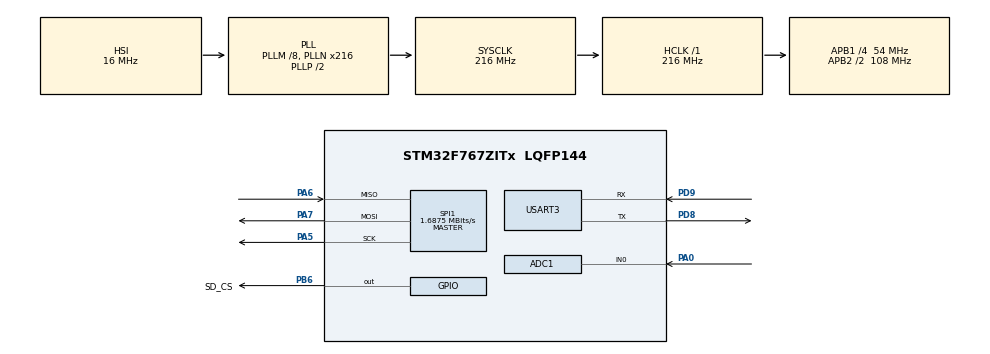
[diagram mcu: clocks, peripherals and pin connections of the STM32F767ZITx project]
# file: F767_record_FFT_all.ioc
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ADC1.Channel-0\#ChannelRegularConversion=ADC_CHANNEL_0
ADC1.DMAContinuousRequests=ENABLE
ADC1.ExternalTrigConv=ADC_EXTERNALTRIGCONV_T2_TRGO
ADC1.NbrOfConversionFlag=1
ADC1.Rank-0\#ChannelRegularConversion=1
ADC1.SamplingTime-0\#ChannelRegularConversion=ADC_SAMPLETIME_28CYCLES
ADC1.master=1
CORTEX_M7.default_mode_Activation=1
Dma.ADC1.0.Direction=DMA_PERIPH_TO_MEMORY
Dma.ADC1.0.FIFOMode=DMA_FIFOMODE_DISABLE
Dma.ADC1.0.Instance=DMA2_Stream0
Dma.ADC1.0.MemDataAlignment=DMA_MDATAALIGN_HALFWORD
Dma.ADC1.0.MemInc=DMA_MINC_ENABLE
Dma.ADC1.0.Mode=DMA_CIRCULAR
Dma.ADC1.0.PeriphDataAlignment=DMA_PDATAALIGN_HALFWORD
Dma.ADC1.0.PeriphInc=DMA_PINC_DISABLE
Dma.ADC1.0.Priority=DMA_PRIORITY_HIGH
Dma.Request0=ADC1
FATFS._CODE_PAGE=437
Mcu.Family=STM32F7
Mcu.Name=STM32F767ZITx
Mcu.Package=LQFP144
NVIC.DMA2_Stream0_IRQn=true\:0\:0\:false\:false\:true\:false\:true\:true
NVIC.PriorityGroup=NVIC_PRIORITYGROUP_4
NVIC.USART3_IRQn=true\:0\:0\:false\:false\:true\:true\:true\:true
PA0/WKUP.Signal=ADCx_IN0
PA5.Mode=Full_Duplex_Master
PA5.Signal=SPI1_SCK
PA6.Mode=Full_Duplex_Master
PA6.Signal=SPI1_MISO
PA7.Mode=Full_Duplex_Master
PA7.Signal=SPI1_MOSI
PB6.GPIO_Label=SD_CS
PB6.GPIO_Speed=GPIO_SPEED_FREQ_HIGH
PB6.PinState=GPIO_PIN_SET
PB6.Signal=GPIO_Output
PD8.Mode=Asynchronous
PD8.Signal=USART3_TX
PD9.Mode=Asynchronous
PD9.Signal=USART3_RX
ProjectManager.HeapSize=0x200
ProjectManager.StackSize=0x400
ProjectManager.TargetToolchain=STM32CubeIDE
RCC.AHBFreq_Value=216000000
RCC.APB1CLKDivider=RCC_HCLK_DIV4
RCC.APB1Freq_Value=54000000
RCC.APB1TimFreq_Value=108000000
RCC.APB2CLKDivider=RCC_HCLK_DIV2
RCC.APB2Freq_Value=108000000
RCC.APB2TimFreq_Value=216000000
RCC.CortexFreq_Value=216000000
RCC.HCLKFreq_Value=216000000
RCC.HSE_VALUE=25000000
RCC.HSI_VALUE=16000000
RCC.LSE_VALUE=32768
RCC.PLLM=8
RCC.PLLN=216
RCC.SYSCLKFreq_VALUE=216000000
RCC.SYSCLKSource=RCC_SYSCLKSOURCE_PLLCLK
RCC.USBFreq_Value=216000000
RCC.VCOOutputFreq_Value=432000000
SH.ADCx_IN0.0=ADC1_IN0,IN0
SPI1.BaudRatePrescaler=SPI_BAUDRATEPRESCALER_64
SPI1.CalculateBaudRate=1.6875 MBits/s
SPI1.DataSize=SPI_DATASIZE_8BIT
SPI1.Direction=SPI_DIRECTION_2LINES
SPI1.Mode=SPI_MODE_MASTER
SPI1.NSSPMode=SPI_NSS_PULSE_DISABLE
SPI1.VirtualType=VM_MASTER
TIM2.Period=3374
TIM2.TIM_MasterOutputTrigger=TIM_TRGO_UPDATE
TIM2.TIM_MasterSlaveMode=TIM_MASTERSLAVEMODE_DISABLE
USART3.VirtualMode-Asynchronous=VM_ASYNC
VP_FATFS_VS_Generic.Mode=User_defined
VP_TIM2_VS_ClockSourceINT.Mode=Internal
board=custom

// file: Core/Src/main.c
/* USER CODE BEGIN Header */
/* F767_record_FFT_all */
/**
  ******************************************************************************
  * @file           : main.c
  * @brief          : Main program body
  ******************************************************************************
  * @attention
  *
  * Copyright (c) 2026 STMicroelectronics.
  * All rights reserved.
  *
  * This software is licensed under terms that can be found in the LICENSE file
  * in the root directory of this software component.
  * If no LICENSE file comes with this software, it is provided AS-IS.
  *
  ******************************************************************************
  */
/* USER CODE END Header */
#include "main.h"
#include "adc.h"
#include "dma.h"
#include "fatfs.h"
#include "spi.h"
#include "tim.h"
#include "usart.h"
#include "gpio.h"

/* USER CODE BEGIN Includes */
#include "app_main.h"
/* USER CODE END Includes */

void SystemClock_Config(void);
static void MPU_Config(void);

int main(void)
{

  /* MPU Configuration--------------------------------------------------------*/
  MPU_Config();

  /* MCU Configuration--------------------------------------------------------*/

  /* Reset of all peripherals, Initializes the Flash interface and the Systick. */
  HAL_Init();

  /* Configure the system clock */
  SystemClock_Config();

  /* Initialize all configured peripherals */
  MX_GPIO_Init();
  MX_DMA_Init();
  MX_ADC1_Init();
  MX_TIM2_Init();
  MX_SPI1_Init();
  MX_USART3_UART_Init();
  MX_FATFS_Init();
  /* USER CODE BEGIN 2 */
  // HAL_UART_Transmit(&huart3, (uint8_t*)"MAIN START\r\n", 12, 1000);
  APP_Init();
  /* USER CODE END 2 */

  /* Infinite loop */
  /* USER CODE BEGIN WHILE */
  while (1)
  {
    // HAL_UART_Transmit(&huart3, (uint8_t*)"HELLO\r\n", 7, 1000);
    APP_Loop();
    /* USER CODE END WHILE */

  }
}

void SystemClock_Config(void)
{
  RCC_OscInitTypeDef RCC_OscInitStruct = {0};
  RCC_ClkInitTypeDef RCC_ClkInitStruct = {0};

  /** Configure the main internal regulator output voltage
  */
  __HAL_RCC_PWR_CLK_ENABLE();
  __HAL_PWR_VOLTAGESCALING_CONFIG(PWR_REGULATOR_VOLTAGE_SCALE1);

  /** Initializes the RCC Oscillators according to the specified parameters
  * in the RCC_OscInitTypeDef structure.
  */
  RCC_OscInitStruct.OscillatorType = RCC_OSCILLATORTYPE_HSI;
  RCC_OscInitStruct.HSIState = RCC_HSI_ON;
  RCC_OscInitStruct.HSICalibrationValue = RCC_HSICALIBRATION_DEFAULT;
  RCC_OscInitStruct.PLL.PLLState = RCC_PLL_ON;
  RCC_OscInitStruct.PLL.PLLSource = RCC_PLLSOURCE_HSI;
  RCC_OscInitStruct.PLL.PLLM = 8;
  RCC_OscInitStruct.PLL.PLLN = 216;
  RCC_OscInitStruct.PLL.PLLP = RCC_PLLP_DIV2;
  RCC_OscInitStruct.PLL.PLLQ = 2;
  RCC_OscInitStruct.PLL.PLLR = 2;
  if (HAL_RCC_OscConfig(&RCC_OscInitStruct) != HAL_OK)
  {
    Error_Handler();
  }

  /** Activate the Over-Drive mode
  */
  if (HAL_PWREx_EnableOverDrive() != HAL_OK)
  {
    Error_Handler();
  }

  /** Initializes the CPU, AHB and APB buses clocks
  */
  RCC_ClkInitStruct.ClockType = RCC_CLOCKTYPE_HCLK|RCC_CLOCKTYPE_SYSCLK
                              |RCC_CLOCKTYPE_PCLK1|RCC_CLOCKTYPE_PCLK2;
  RCC_ClkInitStruct.SYSCLKSource = RCC_SYSCLKSOURCE_PLLCLK;
  RCC_ClkInitStruct.AHBCLKDivider = RCC_SYSCLK_DIV1;
  RCC_ClkInitStruct.APB1CLKDivider = RCC_HCLK_DIV4;
  RCC_ClkInitStruct.APB2CLKDivider = RCC_HCLK_DIV2;

  if (HAL_RCC_ClockConfig(&RCC_ClkInitStruct, FLASH_LATENCY_7) != HAL_OK)
  {
    Error_Handler();
  }
}

/* USER CODE BEGIN 4 */
void HAL_ADC_ConvHalfCpltCallback(ADC_HandleTypeDef* hadc)
{
  if (hadc->Instance == ADC1)
  {
    APP_ADC_HalfCallback();
  } // end if
} // end function HAL_ADC_ConvHalfCpltCallback

void HAL_ADC_ConvCpltCallback(ADC_HandleTypeDef* hadc)
{
  if (hadc->Instance == ADC1)
  {
    APP_ADC_FullCallback();
  } // end if
} // end function HAL_ADC_ConvCpltCallback
/* USER CODE END 4 */

 /* MPU Configuration */

void MPU_Config(void)
{
  MPU_Region_InitTypeDef MPU_InitStruct = {0};

  /* Disables the MPU */
  HAL_MPU_Disable();

  /** Initializes and configures the Region and the memory to be protected
  */
  MPU_InitStruct.Enable = MPU_REGION_ENABLE;
  MPU_InitStruct.Number = MPU_REGION_NUMBER0;
  MPU_InitStruct.BaseAddress = 0x0;
  MPU_InitStruct.Size = MPU_REGION_SIZE_4GB;
  MPU_InitStruct.SubRegionDisable = 0x87;
  MPU_InitStruct.TypeExtField = MPU_TEX_LEVEL0;
  MPU_InitStruct.AccessPermission = MPU_REGION_NO_ACCESS;
  MPU_InitStruct.DisableExec = MPU_INSTRUCTION_ACCESS_DISABLE;
  MPU_InitStruct.IsShareable = MPU_ACCESS_SHAREABLE;
  MPU_InitStruct.IsCacheable = MPU_ACCESS_NOT_CACHEABLE;
  MPU_InitStruct.IsBufferable = MPU_ACCESS_NOT_BUFFERABLE;

  HAL_MPU_ConfigRegion(&MPU_InitStruct);
  /* Enables the MPU */
  HAL_MPU_Enable(MPU_PRIVILEGED_DEFAULT);

}

void Error_Handler(void)
{
  __disable_irq();
  while (1)
  {
  }
}
